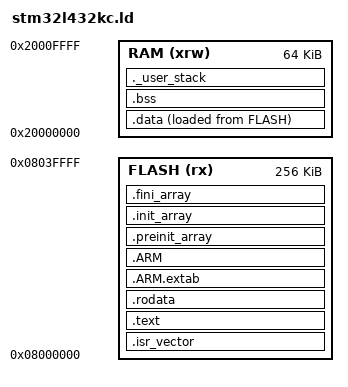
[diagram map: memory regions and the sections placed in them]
ENTRY(Reset_Handler)

/* Highest address of the user mode stack */
_estack = 0x20010000;
/* Generate a link error if stack don't fit into RAM */
_Min_Stack_Size = 0x800; /* required amount of stack */

MEMORY
{
RAM (xrw)      : ORIGIN = 0x20000000, LENGTH = 64K
FLASH (rx)      : ORIGIN = 0x8000000, LENGTH = 256K
}

SECTIONS
{
  /* Interrupt vector table */
  .isr_vector :
  {
    . = ALIGN(8);
    KEEP(*(.isr_vector))
    . = ALIGN(8);
  } >FLASH

  /* generated code */
  .text :
  {
    . = ALIGN(8);
    *(.text)           /* .text sections (code) */
    *(.text*)          /* .text* sections (code) */
    *(.eh_frame)

    KEEP (*(.init))
    KEEP (*(.fini))

    . = ALIGN(8);
    _etext = .;
  } >FLASH

  /* Read-only data */
  .rodata :
  {
    . = ALIGN(8);
    *(.rodata)
    *(.rodata*)
    . = ALIGN(8);
  } >FLASH

  .ARM.extab   : 
  { 
  . = ALIGN(8);
  *(.ARM.extab* .gnu.linkonce.armextab.*)
  . = ALIGN(8);
  } >FLASH
  .ARM : {
  . = ALIGN(8);
    __exidx_start = .;
    *(.ARM.exidx*)
    __exidx_end = .;
  . = ALIGN(8);
  } >FLASH

  .preinit_array     :
  {
  . = ALIGN(8);
    PROVIDE_HIDDEN (__preinit_array_start = .);
    KEEP (*(.preinit_array*))
    PROVIDE_HIDDEN (__preinit_array_end = .);
  . = ALIGN(8);
  } >FLASH
  
  .init_array :
  {
  . = ALIGN(8);
    PROVIDE_HIDDEN (__init_array_start = .);
    KEEP (*(SORT(.init_array.*)))
    KEEP (*(.init_array*))
    PROVIDE_HIDDEN (__init_array_end = .);
  . = ALIGN(8);
  } >FLASH
  .fini_array :
  {
  . = ALIGN(8);
    PROVIDE_HIDDEN (__fini_array_start = .);
    KEEP (*(SORT(.fini_array.*)))
    KEEP (*(.fini_array*))
    PROVIDE_HIDDEN (__fini_array_end = .);
  . = ALIGN(8);
  } >FLASH

  /* start address of data section in RAM */
  _sidata = LOADADDR(.data);

  .data : 
  {
    . = ALIGN(8);
    _sdata = .;        /* start of data section in FLASH */
    *(.data)
    *(.data*)

    . = ALIGN(8);
    _edata = .;
  } >RAM AT> FLASH

  
  /* Uninitialized data section */
  . = ALIGN(4);
  .bss :
  {
    _sbss = .;
    __bss_start__ = _sbss;
    *(.bss)
    *(.bss*)
    *(COMMON)

    . = ALIGN(4);
    _ebss = .;
    __bss_end__ = _ebss;
  } >RAM

  /* User_stack section, used to check that there is enough RAM left */
  ._user_stack :
  {
    . = ALIGN(8);
    PROVIDE ( end = . );
    PROVIDE ( _end = . );
    . = . + _Min_Stack_Size;
    . = ALIGN(8);
  } >RAM

  

  /DISCARD/ :
  {
    libc.a ( * )
    libm.a ( * )
    libgcc.a ( * )
  }

  .ARM.attributes 0 : { *(.ARM.attributes) }
}


